# nrf7120E_enga_application register map
Vendor: Nordic Semiconductor; Series: nrf71; File version: 1
CPU: CM33 r0p4, little endian, MPU, FPU, 3 interrupt priority bits, 270 interrupts, 4 SAU regions
Registers are 32-bit, read-write, reset 0x0 unless marked. A register's access mark holds for its fields unless they carry their own. Offsets are from the block's base; [hi:lo] are bit positions; lines under a group give offsets from that group; {n}, {i} and the like mark numbered series; 'fields as' and 'values as' point back to an identical list.

## GLOBAL_MSPI00_NS — Multi serial peripheral interface 0
Base 0x4005B000
Same registers: GLOBAL_MSPI01_NS 0x4005C000, GLOBAL_MSPI00_S 0x5005B000, GLOBAL_MSPI01_S 0x5005C000
0x00 TASKS_START wo — Start operation.
  [0] TASKS_START
    1=Trigger task
0x04 TASKS_RESET wo — Reset the MSPI
  [0] TASKS_RESET
    1=Trigger task
0x08 TASKS_ACQUIRESEMAPHORE wo — Request the semaphore This task is exclusive to the 'peripheral' configuration
  [0] TASKS_ACQUIRESEMAPHORE
    1=Trigger task
0x0C TASKS_RELEASESEMAPHORE wo — Release the semaphore This task is exclusive to the 'peripheral' configuration
  [0] TASKS_RELEASESEMAPHORE
    1=Trigger task
0x100 EVENTS_CORE — Interrupt from the MSPI core
  [0] EVENTS_CORE
    0=NotGenerated (Event not generated); 1=Generated (Event generated)
0x104 EVENTS_DMA group — Peripheral events.
  0x00 EVENTS_DONE group — Peripheral events.
    0x00 LIST — Descriptor list is complete.
      [0] LIST
        values as EVENTS_CORE.EVENTS_CORE
    0x04 LISTPART — Descriptor list is partially complete. Threshold in CONFIG.LISTPARTTHRESH register has been passed.
      [0] LISTPART
        values as EVENTS_CORE.EVENTS_CORE
    0x08 SELECTJOB — Selected job is completed. Selection is done via CONFIG.SELECTJOBENABLE.
      [0] SELECTJOB
        values as EVENTS_CORE.EVENTS_CORE
    0x0C DATA — A job has been completed, i.e. the job's data has been completely transferred either to AXI or DMA bus, depending on direction.
      [0] DATA
        values as EVENTS_CORE.EVENTS_CORE
    0x10 JOB — A job has been fetched from the joblist.
      [0] JOB
        values as EVENTS_CORE.EVENTS_CORE
  0x14 ERROR — AXI bus error received.
    [0] ERROR
      values as EVENTS_CORE.EVENTS_CORE
  0x18 PAUSED — DMA paused with task TASKS_PAUSE.
    [0] PAUSED
      values as EVENTS_CORE.EVENTS_CORE
  0x1C RESET — DMA reset with task TASKS_RESET.
    [0] RESET
      values as EVENTS_CORE.EVENTS_CORE
  0x20 DONE — DMA transfer done
    [0] DONE
      values as EVENTS_CORE.EVENTS_CORE
  0x24 TXUNEXPECTEDIDLE — The MSPI core has gone into idle state at an unexpected time, this can happen if the TX buffer underflows, this event is followed by either DONE or ABORTED event.
    [0] TXUNEXPECTEDIDLE
      values as EVENTS_CORE.EVENTS_CORE
  0x28 INTERNALBUSERROR — An error occurred during the transfer of data internally in the MSPI, followed by either DONE or ABORTED event.
    [0] INTERNALBUSERROR
      values as EVENTS_CORE.EVENTS_CORE
  0x2C ABORTED — The MSPI DMA has aborted due to an error given in a separate event, and has attempted to complete any ongoing transactions, and stopped. The MSPI DMA is ready for a new transaction.
    [0] ABORTED
      values as EVENTS_CORE.EVENTS_CORE
0x134 EVENTS_IDLE — This event signifies that the MSPI core is no longer busy
  [0] EVENTS_IDLE
    values as EVENTS_CORE.EVENTS_CORE
0x138 EVENTS_OVERFLOW — The MSPI peripheral has received the specified number of bytes. Any data received after this event will be discarded if a new RX buffer has not been configured. This event is exclusive to the 'peripheral' configuration
  [0] EVENTS_OVERFLOW
    values as EVENTS_CORE.EVENTS_CORE
0x140 EVENTS_ACQUIRED — The semaphore has been acquired by the CPU This event is exclusive to the 'peripheral' configuration
  [0] EVENTS_ACQUIRED
    values as EVENTS_CORE.EVENTS_CORE
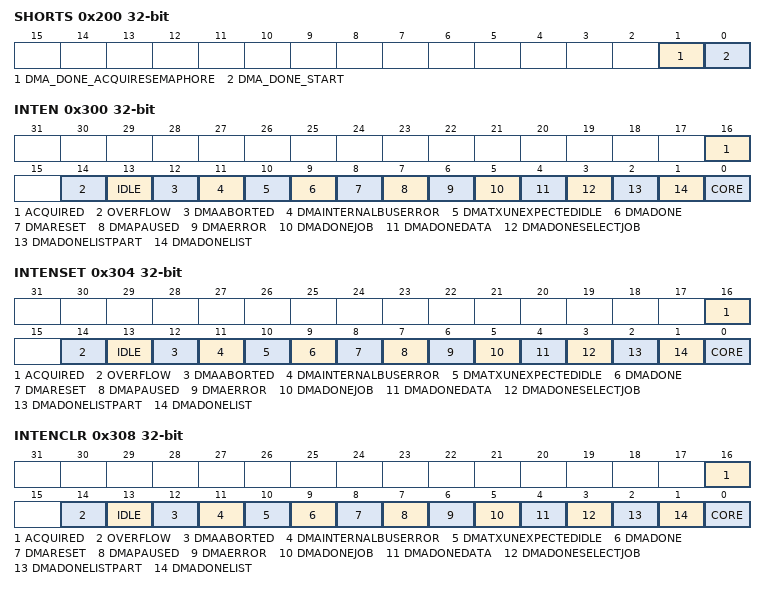
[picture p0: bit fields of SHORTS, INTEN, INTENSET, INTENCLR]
0x200 SHORTS — Shortcuts between local events and tasks
  [1] DMA_DONE_ACQUIRESEMAPHORE — Shortcut between event DMA.DONE and task ACQUIRESEMAPHORE
    0=Disabled (Disable shortcut); 1=Enabled (Enable shortcut)
  [0] DMA_DONE_START — Shortcut between event DMA.DONE and task START
    0=Disabled (Disable shortcut); 1=Enabled (Enable shortcut)
0x300 INTEN — Enable or disable interrupt
  [all] fields
    0=Disabled; 1=Enabled
  [16] ACQUIRED — Enable or disable interrupt for event ACQUIRED
  [14] OVERFLOW — Enable or disable interrupt for event OVERFLOW
  [13] IDLE — Enable or disable interrupt for event IDLE
  [12] DMAABORTED — Enable or disable interrupt for event DMAABORTED
  [11] DMAINTERNALBUSERROR — Enable or disable interrupt for event DMAINTERNALBUSERROR
  [10] DMATXUNEXPECTEDIDLE — Enable or disable interrupt for event DMATXUNEXPECTEDIDLE
  [9] DMADONE — Enable or disable interrupt for event DMADONE
  [8] DMARESET — Enable or disable interrupt for event DMARESET
  [7] DMAPAUSED — Enable or disable interrupt for event DMAPAUSED
  [6] DMAERROR — Enable or disable interrupt for event DMAERROR
  [5] DMADONEJOB — Enable or disable interrupt for event DMADONEJOB
  [4] DMADONEDATA — Enable or disable interrupt for event DMADONEDATA
  [3] DMADONESELECTJOB — Enable or disable interrupt for event DMADONESELECTJOB
  [2] DMADONELISTPART — Enable or disable interrupt for event DMADONELISTPART
  [1] DMADONELIST — Enable or disable interrupt for event DMADONELIST
  [0] CORE — Enable or disable interrupt for event CORE
0x304 INTENSET — Enable interrupt
  [all] fields
    on read: 0=Disabled (Read: Disabled); 1=Enabled (Read: Enabled) | on write: 1=Set (Enable)
  [16] ACQUIRED write-1-sets — Write '1' to enable interrupt for event ACQUIRED
  [14] OVERFLOW write-1-sets — Write '1' to enable interrupt for event OVERFLOW
  [13] IDLE write-1-sets — Write '1' to enable interrupt for event IDLE
  [12] DMAABORTED write-1-sets — Write '1' to enable interrupt for event DMAABORTED
  [11] DMAINTERNALBUSERROR write-1-sets — Write '1' to enable interrupt for event DMAINTERNALBUSERROR
  [10] DMATXUNEXPECTEDIDLE write-1-sets — Write '1' to enable interrupt for event DMATXUNEXPECTEDIDLE
  [9] DMADONE write-1-sets — Write '1' to enable interrupt for event DMADONE
  [8] DMARESET write-1-sets — Write '1' to enable interrupt for event DMARESET
  [7] DMAPAUSED write-1-sets — Write '1' to enable interrupt for event DMAPAUSED
  [6] DMAERROR write-1-sets — Write '1' to enable interrupt for event DMAERROR
  [5] DMADONEJOB write-1-sets — Write '1' to enable interrupt for event DMADONEJOB
  [4] DMADONEDATA write-1-sets — Write '1' to enable interrupt for event DMADONEDATA
  [3] DMADONESELECTJOB write-1-sets — Write '1' to enable interrupt for event DMADONESELECTJOB
  [2] DMADONELISTPART write-1-sets — Write '1' to enable interrupt for event DMADONELISTPART
  [1] DMADONELIST write-1-sets — Write '1' to enable interrupt for event DMADONELIST
  [0] CORE write-1-sets — Write '1' to enable interrupt for event CORE
0x308 INTENCLR — Disable interrupt
  [all] fields
    on read: 0=Disabled (Read: Disabled); 1=Enabled (Read: Enabled) | on write: 1=Clear (Disable)
  [16] ACQUIRED write-1-clears — Write '1' to disable interrupt for event ACQUIRED
  [14] OVERFLOW write-1-clears — Write '1' to disable interrupt for event OVERFLOW
  [13] IDLE write-1-clears — Write '1' to disable interrupt for event IDLE
  [12] DMAABORTED write-1-clears — Write '1' to disable interrupt for event DMAABORTED
  [11] DMAINTERNALBUSERROR write-1-clears — Write '1' to disable interrupt for event DMAINTERNALBUSERROR
  [10] DMATXUNEXPECTEDIDLE write-1-clears — Write '1' to disable interrupt for event DMATXUNEXPECTEDIDLE
  [9] DMADONE write-1-clears — Write '1' to disable interrupt for event DMADONE
  [8] DMARESET write-1-clears — Write '1' to disable interrupt for event DMARESET
  [7] DMAPAUSED write-1-clears — Write '1' to disable interrupt for event DMAPAUSED
  [6] DMAERROR write-1-clears — Write '1' to disable interrupt for event DMAERROR
  [5] DMADONEJOB write-1-clears — Write '1' to disable interrupt for event DMADONEJOB
  [4] DMADONEDATA write-1-clears — Write '1' to disable interrupt for event DMADONEDATA
  [3] DMADONESELECTJOB write-1-clears — Write '1' to disable interrupt for event DMADONESELECTJOB
  [2] DMADONELISTPART write-1-clears — Write '1' to disable interrupt for event DMADONELISTPART
  [1] DMADONELIST write-1-clears — Write '1' to disable interrupt for event DMADONELIST
  [0] CORE write-1-clears — Write '1' to disable interrupt for event CORE
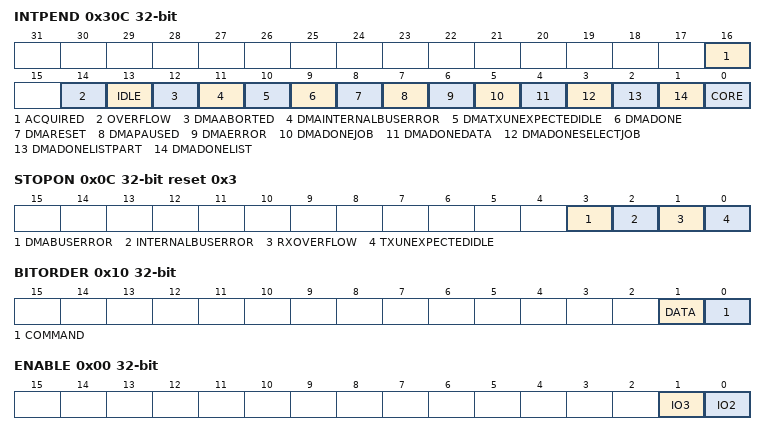
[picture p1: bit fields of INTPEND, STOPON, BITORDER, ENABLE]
0x30C INTPEND ro — Pending interrupts
  [all] fields
    on read: 0=NotPending (Read: Not pending); 1=Pending (Read: Pending)
  [16] ACQUIRED — Read pending status of interrupt for event ACQUIRED
  [14] OVERFLOW — Read pending status of interrupt for event OVERFLOW
  [13] IDLE — Read pending status of interrupt for event IDLE
  [12] DMAABORTED — Read pending status of interrupt for event DMAABORTED
  [11] DMAINTERNALBUSERROR — Read pending status of interrupt for event DMAINTERNALBUSERROR
  [10] DMATXUNEXPECTEDIDLE — Read pending status of interrupt for event DMATXUNEXPECTEDIDLE
  [9] DMADONE — Read pending status of interrupt for event DMADONE
  [8] DMARESET — Read pending status of interrupt for event DMARESET
  [7] DMAPAUSED — Read pending status of interrupt for event DMAPAUSED
  [6] DMAERROR — Read pending status of interrupt for event DMAERROR
  [5] DMADONEJOB — Read pending status of interrupt for event DMADONEJOB
  [4] DMADONEDATA — Read pending status of interrupt for event DMADONEDATA
  [3] DMADONESELECTJOB — Read pending status of interrupt for event DMADONESELECTJOB
  [2] DMADONELISTPART — Read pending status of interrupt for event DMADONELISTPART
  [1] DMADONELIST — Read pending status of interrupt for event DMADONELIST
  [0] CORE — Read pending status of interrupt for event CORE
0x400 ENABLE — Enables the MSPI
  [0] ENABLE — Enable the MSPI
0x404 CONFIG group — Unspecified
  0x00 TXBURSTLENGTH reset 0x8 — Transmit burst length
    [4:0] AMOUNT — Number of buffer lines
  0x04 RXBURSTLENGTH reset 0x8 — Receive burst length
    [4:0] AMOUNT — Number of buffer lines
  0x08 RXTRANSFERLENGTH reset 0x10 — Receive transfer full length
    [17:0] AMOUNT — Number of buffer lines
  0x0C STOPON reset 0x3 — Stop the DMA if the CORE goes into any of the enabled states.
    [3] DMABUSERROR — Terminate the transaction if a DMA.ERROR event is detected.
      0=Disabled; 1=Enabled
    [2] INTERNALBUSERROR — Terminate the transaction if a INTERNALBUSERROR event is detected.
      0=Disabled; 1=Enabled
    [1] RXOVERFLOW — This condition occurrs if the DMA attempts to write to the RX buffer in the CORE, but the buffer is full. When this bit is enabled the DMA will stop when the CORE buffer experiences a rx buffer overflow
      0=Disabled (Stop on rx overflow disabled.); 1=Enabled (Stop on rx overflow enabled.)
    [0] TXUNEXPECTEDIDLE — The CORE will go into idle if the CORE buffer is emptied, if the DMA still has data to transfer the CORE is not expected to go into idle state. This constitutes a buffer underflow. The CORE migth also go into idle if an error occurs.
      0=Disabled (Stop on tx unexpected idle disabled.); 1=Enabled (Stop on tx unexpected idle enabled.)
0x418 FORMAT group — Unspecified
  0x00 DFS — Data frame size
    [5:0] DFS
  0x04 BPP — Bits per pixel
    [5:0] BPP
      0=Reordering of pixels disabled; 4=4 Bits per pixel; 8=8 Bits per pixel; 16=16 Bits per pixel
  0x08 PIXELS — Number of pixels following the command
    [17:0] PIXELS — Number of pixels
  0x0C CILEN — Command/Instruction length
    [1:0] CILEN — Number of words
  0x10 BITORDER — This register selects if the data collected from system memory is transmitted MSB first or LSB first.
    [1] DATA — Selects the bit order of data
      0=MSB (Transmit MSB first); 1=LSB (Transmit LSB first)
    [0] COMMAND — Selects the bit order of command and address
      0=MSB (Transmit MSB first); 1=LSB (Transmit LSB first)
0x42C CUSTCMD group — Unspecified
  0x00 ENABLE — Custom command enable
    [1] IO3 — Enable custom command mode for IO3
      0=Disabled (Unspecified); 1=Enabled (Unspecified)
    [0] IO2 — Enable custom command mode for IO2
      0=Disabled (Unspecified); 1=Enabled (Unspecified)
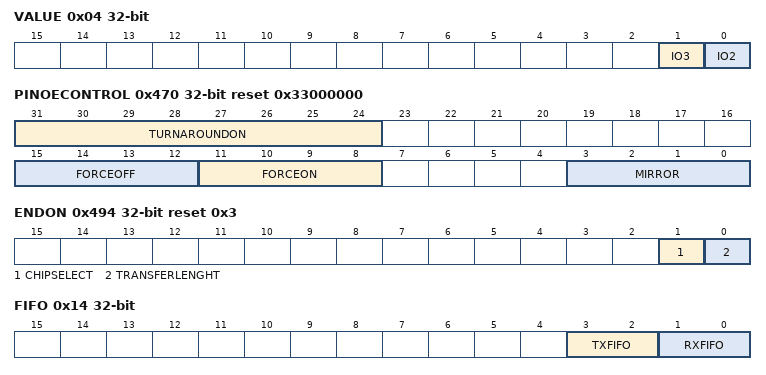
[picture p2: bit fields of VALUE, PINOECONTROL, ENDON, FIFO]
  0x04 VALUE — Custom command value
    [1] IO3 — Value to override IO3 to in custom command mode
    [0] IO2 — Value to override IO2 to in custom command mode
0x470 PINOECONTROL reset 0x33000000 — Override and control the output enable signal to the GPIO pads
  [31:24] TURNAROUNDON — Time needed for pin output driver to turn on (in core clock cycles)
    0=Disabled (Unspecified)
  [15:12] FORCEOFF — Force pin direction to be input
    1=EnableIO0 (Forcing off enabled output for IO0); 2=EnableIO1 (Forcing off enabled output for IO1); 4=EnableIO2 (Forcing off enabled output for IO2); 8=EnableIO3 (Forcing off enabled output for IO3); 15=EnableAll (Forcing off enabled output for all data lines); 0=Disabled (Forcing off Output Enable is disabled)
  [11:8] FORCEON — Force pin direction to be output
    1=EnableIO0 (Forcing on enabled output for IO0); 2=EnableIO1 (Forcing on enabled output for IO1); 4=EnableIO2 (Forcing on enabled output for IO2); 8=EnableIO3 (Forcing on enabled output for IO3); 15=EnableAll (Forcing on enabled output for all data lines); 0=Disabled (Forcing on Output Enable is disabled)
  [3:0] MIRROR — Enable mirroring of output enable of pin 0 for corresponding bit
    1=EnableIO0 (Enable mirroring on output enable for IO0); 2=EnableIO1 (Enable mirroring on output enable for IO1); 4=EnableIO2 (Enable mirroring on output enable for IO2); 8=EnableIO3 (Enable mirroring on output enable for IO3); 15=EnableAll (Enable mirroring on output enable for all data lines); 0=Disabled (Enabling mirroring on Output Enable is disabled)
0x490 TMOD — Transfer Mode of the MSPI when used as peripheral This register is exclusive to the 'peripheral' configuration
  [1:0] TMOD
    1=TXONLY (Transmit only mode; Or Write in enhanced SPI operating mode); 2=RXONLY (Receive only mode; Or Read in enhanced SPI operating mode)
0x494 ENDON reset 0x3 — End the DMA if the MSPI meets any of the defined states This task is exclusive to the 'peripheral' configuration
  [1] CHIPSELECT — End the DMA transaction when chip select goes inactive
  [0] TRANSFERLENGHT ro — End the DMA transaction when the transferlength has been met
0x4B0 RXD group — Unspecified
  0x00 AMOUNT ro — DMA data amount
    [23:0] AMOUNT
0x4D0 TXD group — Unspecified
  0x00 AMOUNT ro — DMA data amount
    [23:0] AMOUNT
0x500 DMA group — Unspecified
  0x00 STATUS group — EasyVDMA status registers.
    0x00 BYTECOUNT ro — Number of bytes sent or received during processing of current descriptor list
    0x04 ATTRIBUTE ro — Latest job attribute being processed.
      [5:0] ATTRIBUTE
    0x08 ADDRESS ro — Latest address being accessed.
    0x0C JOBCOUNT ro — Number of completed jobs in current descriptor list.
    0x10 BUSERROR ro — AXI bus error status.
      [2:0] BUSERROR — AXI bus error type
        0=NoError (There are no errors.); 1=ReadError (Error related to memory when reading joblist, or error related to memory/register when reading data.); 2=ReadDecodeError (Error related to the joblist address when reading joblist, or error related to address when reading memory/register.); 3=WriteError (Error related to memory/register when writing data.); 4=WriteDecodeError (Error related to the memory/register address when writing data.)
    0x14 FIFO ro — Data fifo status.
      [3:2] TXFIFO — Peripheral-to-Memory direction data fifo status
        0=Empty (Fifo is empty.); 1=NotEmpty (Fifo contains data.); 2=Full (Fifo is full.)
      [1:0] RXFIFO — Memory-to-Peripheral direction data fifo status
        values as TXFIFO
    0x18 ACTIVE ro — DMA activity state.
      [0] ACTIVE
        0=Idle (DMA is in idle state.); 1=Active (Data is being transferred.)
  0x100 CONFIG group — EasyVDMA configuration registers
    0x00 BUFFERFILL — Data to be used when data is sent with BufferFill attribute
      [7:0] BUFFERFILL
    0x04 LISTPTR — Start address of descriptor list
    0x08 LISTPARTTHRESH — Number of jobs to process before generating event EVENTS_DONE.LISTPART to signal that descriptor list is partially completed.
      [15:0] LISTPARTTHRESH — Threshold value.
0x900 CONTROLLERCORE group — Unspecified
  0x00 CORE group — Unspecified
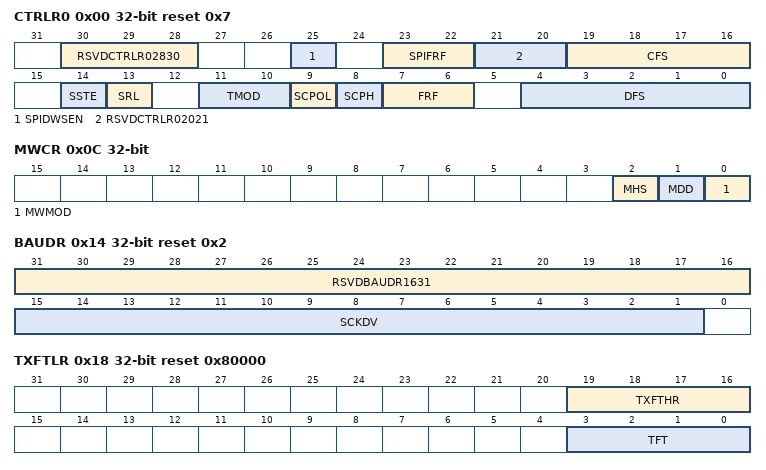
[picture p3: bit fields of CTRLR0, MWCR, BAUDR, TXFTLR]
    0x00 CTRLR0 reset 0x7 — Control Register 0
      [30:28] RSVDCTRLR02830 ro
      [25] SPIDWSEN — Enable Dynamic wait states in SPI mode of operation. This field is only applicable when CTRLR0.FRF is set to 0 (Motorola SPI Frame Format).
        0=DISABLE (Disable SPI Dynamic Wait State); 1=ENABLE (Enable SPI Dynamic Wait State)
      [23:22] SPIFRF — SPI Frame Format
        0=SPI_STANDARD (Standard SPI Format); 1=SPI_DUAL (Dual SPI Format); 2=SPI_QUAD (Quad SPI Format); 3=SPI_OCTAL (Octal SPI Format)
      [21:20] RSVDCTRLR02021 ro
      [19:16] CFS — Control Frame Size.
        {v}=SIZE_{v+1:02}_BIT ({v+1:02}-bit Control Word) (v=0..15)
      [14] SSTE — Target Select Toggle Enable.
        0=TOGGLE_DISABLE (ss_*_n will stay low and sclk will run continuously for the duration of the transfer); 1=TOGGLE_EN (ss_*_n line will toggle between consecutive data frames, with the serial clock (sclk) being held to its default value while ss_*_n is high)
      [13] SRL — Shift Register Loop.
        0=NORMAL_MODE (Normal mode operation); 1=TESTING_MODE (Test Mode Operation)
      [11:10] TMOD — Transfer Mode.
        0=TX_AND_RX (Transmit & Receive; Not Applicable in enhanced SPI operating mode or when SSIC_HAS_TX_RX_EN is set to 0); 1=TX_ONLY (Transmit only mode; Or Write in enhanced SPI operating mode); 2=RX_ONLY (Receive only mode; Or Read in enhanced SPI operating mode); 3=EEPROM_READ (EEPROM Read mode; Not Applicable in enhanced SPI operating mode)
      [9] SCPOL — Serial Clock Polarity.
        0=INACTIVE_LOW (Inactive state of serial clock is low); 1=INACTIVE_HIGH (Inactive state of serial clock is high)
      [8] SCPH — Serial Clock Phase.
        0=MIDDLE_BIT (Serial clock toggles in middle of first bit); 1=START_BIT (Serial clock toggles at start of first bit)
      [7:6] FRF — Frame Format.
        0=SPI (Motorola SPI Frame Format); 1=SSP (Texas Instruments SSP Frame Format); 2=MICROWIRE (National Semiconductors Microwire Frame Format)
      [4:0] DFS — Data Frame Size.
        {v}=DFS_{v+1:02}_BIT ({v+1:02}-bit serial data transfer) (v=3..31)
    0x04 CTRLR1 — Control Register 1
      [15:0] NDF — Number of Data Frames.
    0x08 SSIENR — SSI Enable Register
      [0] SSICEN — SSI Enable.
        0=DISABLE (Disables MSPI CORE); 1=ENABLED (Enables MSPI CORE)
    0x0C MWCR — Microwire Control Register
      [2] MHS — Microwire Handshaking.
        0=DISABLE (handshaking interface is disabled); 1=ENABLED (handshaking interface is enabled)
      [1] MDD — Microwire Control.
        0=RECEIVE (SSI receives data); 1=TRANSMIT (SSI transmits data)
      [0] MWMOD — Microwire Transfer Mode.
        0=NON_SEQUENTIAL (Non-Sequential Transfer); 1=SEQUENTIAL (Sequential Transfer)
    0x10 SER — Target Enable Register
      [3:0] SER — Chip Select Enable Flag.
    0x14 BAUDR reset 0x2 — Baud Rate Select
      [31:16] RSVDBAUDR1631 ro
      [15:1] SCKDV — SSI Clock Divider.
    0x18 TXFTLR reset 0x80000 — Transmit FIFO Threshold Level
      [19:16] TXFTHR — Transfer start FIFO level.
      [3:0] TFT — Transmit FIFO Threshold.
    0x1C RXFTLR — Receive FIFO Threshold Level
      [3:0] RFT — Receive FIFO Threshold.
    0x20 TXFLR — Transmit FIFO Level Register
      [4:0] TXTFL ro — Transmit FIFO Level.
    0x24 RXFLR — Receive FIFO Level Register
      [4:0] RXTFL ro — Receive FIFO Level.
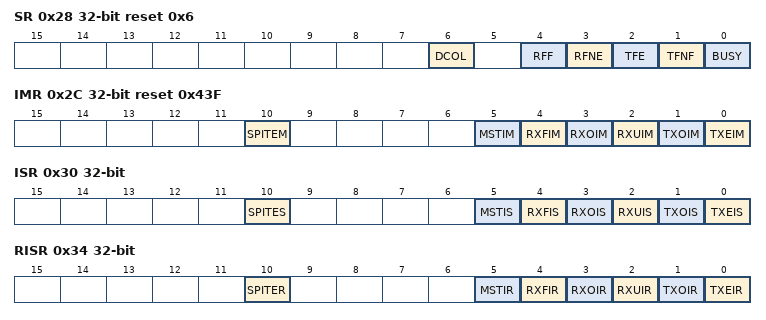
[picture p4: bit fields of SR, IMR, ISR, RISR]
    0x28 SR reset 0x6 — Status Register
      [6] DCOL ro — Data Collision Error.
        0=NO_ERROR_CONDITION; 1=TX_COLLISION_ERROR (Transmit Data Collision Error)
      [4] RFF ro — Receive FIFO Full.
        0=NOT_FULL (Receive FIFO is not full); 1=FULL (Receive FIFO is full)
      [3] RFNE ro — Receive FIFO Not Empty.
        0=EMPTY (Receive FIFO is empty); 1=NOT_EMPTY (Receive FIFO is not empty)
      [2] TFE ro — Transmit FIFO Empty.
        0=NOT_EMPTY (Transmit FIFO is not empty); 1=EMPTY (Transmit FIFO is empty)
      [1] TFNF ro — Transmit FIFO Not Full.
        0=FULL (Tx FIFO is full); 1=NOT_FULL (Tx FIFO is not Full)
      [0] BUSY ro — SSI Busy Flag.
        0=INACTIVE (MSPI CORE is idle or disabled); 1=ACTIVE (MSPI CORE is actively transferring data)
    0x2C IMR reset 0x43F — Interrupt Mask Register
      [10] SPITEM — SPI Transmit Error Interrupt Mask
        0=MASKED (ssi_spite_intr interrupt is masked); 1=UNMASKED (ssi_spite_intr interrupt is not masked)
      [5] MSTIM — Multi-Controller Contention Interrupt Mask. This bit field is not present if the MSPI CORE is configured as a serial-target device.
        0=MASKED (ssi_mst_intr interrupt is masked); 1=UNMASKED (ssi_mst_intr interrupt is not masked)
      [4] RXFIM — Receive FIFO Full Interrupt Mask
        0=MASKED (ssi_rxf_intr interrupt is masked); 1=UNMASKED (ssi_rxf_intr interrupt is not masked)
      [3] RXOIM — Receive FIFO Overflow Interrupt Mask
        0=MASKED (ssi_rxo_intr interrupt is masked); 1=UNMASKED (ssi_rxo_intr interrupt is not masked)
      [2] RXUIM — Receive FIFO Underflow Interrupt Mask
        0=MASKED (ssi_rxu_intr interrupt is masked); 1=UNMASKED (ssi_rxu_intr interrupt is not masked)
      [1] TXOIM — Transmit FIFO Overflow Interrupt Mask
        0=MASKED (ssi_txo_intr interrupt is masked); 1=UNMASKED (ssi_txo_intr interrupt is not masked)
      [0] TXEIM — Transmit FIFO Empty Interrupt Mask
        0=MASKED (ssi_txe_intr interrupt is masked); 1=UNMASKED (ssi_txe_intr interrupt is not masked)
    0x30 ISR — Interrupt Status Register
      [10] SPITES ro — SPI Transmit Error Interrupt
        0=INACTIVE (ssi_spite_intr interrupt is not active after masking); 1=ACTIVE (ssi_spite_intr interrupt is active after masking)
      [5] MSTIS ro — Multi-Controller Contention Interrupt Status. This bit field is not present
        0=INACTIVE (ssi_mst_intr interrupt is not active after masking); 1=ACTIVE (ssi_mst_intr interrupt is active after masking)
      [4] RXFIS ro — Receive FIFO Full Interrupt Status
        0=INACTIVE (ssi_rxf_intr interrupt is not active after masking); 1=ACTIVE (ssi_rxf_intr interrupt is active after masking)
      [3] RXOIS ro — Receive FIFO Overflow Interrupt Status
        0=INACTIVE (ssi_rxo_intr interrupt is not active after masking); 1=ACTIVE (ssi_rxo_intr interrupt is active after masking)
      [2] RXUIS ro — Receive FIFO Underflow Interrupt Status
        0=INACTIVE (ssi_rxu_intr interrupt is not active after masking); 1=ACTIVE (ssi_rxu_intr interrupt is active after masking)
      [1] TXOIS ro — Transmit FIFO Overflow Interrupt Status
        0=INACTIVE (ssi_txo_intr interrupt is not active after masking); 1=ACTIVE (ssi_txo_intr interrupt is active after masking)
      [0] TXEIS ro — Transmit FIFO Empty Interrupt Status
        0=INACTIVE (ssi_txe_intr interrupt is not active after masking); 1=ACTIVE (ssi_txe_intr interrupt is active after masking)
    0x34 RISR — Raw Interrupt Status Register
      [10] SPITER ro — SPI Transmit Error Interrupt status.
        0=INACTIVE (ssi_spite_intr interrupt is not active prior to masking); 1=ACTIVE (ssi_spite_intr interrupt is active prior to masking)
      [5] MSTIR ro — Multi-Controller Contention Raw Interrupt Status. This bit field is not present if the MSPI CORE is configured as a serial-target device.
        0=INACTIVE (ssi_mst_intr interrupt is not active prior masking); 1=ACTIVE (ssi_mst_intr interrupt is active prior to masking)
      [4] RXFIR ro — Receive FIFO Full Raw Interrupt Status
        0=INACTIVE (ssi_rxf_intr interrupt is not active prior masking); 1=ACTIVE (ssi_rxf_intr interrupt is active prior to masking)
      [3] RXOIR ro — Receive FIFO Overflow Raw Interrupt Status
        0=INACTIVE (ssi_rxo_intr interrupt is not active prior masking); 1=ACTIVE (ssi_rxo_intr interrupt is active prior to masking)
      [2] RXUIR ro — Receive FIFO Underflow Raw Interrupt Status
        0=INACTIVE (ssi_rxu_intr interrupt is not active prior masking); 1=ACTIVE (ssi_rxu_intr interrupt is active prior to masking)
      [1] TXOIR ro — Transmit FIFO Overflow Raw Interrupt Status
        0=INACTIVE (ssi_txo_intr interrupt is not active prior masking); 1=ACTIVE (ssi_txo_intr interrupt is active prior to masking)
      [0] TXEIR ro — Transmit FIFO Empty Raw Interrupt Status
        0=INACTIVE (ssi_txe_intr interrupt is not active prior masking); 1=ACTIVE (ssi_txe_intr interrupt is active prior to masking)
    0x38 TXEICR — Transmit FIFO Error Interrupt Clear Register Register
      [0] TXEICR ro — Clear Transmit FIFO Overflow/Underflow Interrupt.
    0x3C RXOICR — Receive FIFO Overflow Interrupt Clear Register
      [0] RXOICR ro — Clear Receive FIFO Overflow Interrupt.
    0x40 RXUICR — Receive FIFO Underflow Interrupt Clear Register
      [0] RXUICR ro — Clear Receive FIFO Underflow Interrupt.
    0x44 MSTICR — Multi-Controller Interrupt Clear Register
      [0] MSTICR ro — Clear Multi-Controller Contention Interrupt.
    0x48 ICR — Interrupt Clear Register
      [0] ICR ro — Clear Interrupts.
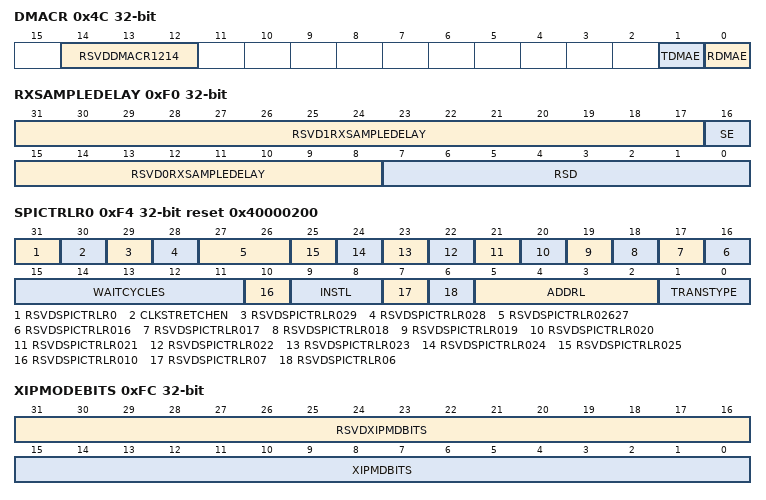
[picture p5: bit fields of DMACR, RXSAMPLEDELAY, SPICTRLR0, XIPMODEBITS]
    0x4C DMACR — DMA Control Register
      [14:12] RSVDDMACR1214 ro
      [1] TDMAE — Transmit DMA Enable. This bit enables/disables the transmit FIFO DMA channel.
        0=DISABLE (Transmit DMA disabled); 1=ENABLED (Transmit DMA enabled)
      [0] RDMAE — Receive DMA Enable. This bit enables/disables the receive FIFO DMA channel.
        0=DISABLE (Receive DMA disabled); 1=ENABLED (Receive DMA enabled)
    0x50 DMATDLR — DMA Transmit Data Level
      [3:0] DMATDL — Transmit Data Level. This bit field controls the level at which a DMA request is made by the transmit logic. It is equal to the watermark level; that is, the dma_tx_req signal is generated when the number of valid data entries in the transmit FIFO is equal to or below this field value, and TDMAE = 1.
    0x54 DMARDLR — DMA Receive Data Level
      [3:0] DMARDL — Receive Data Level. This bit field controls the level at which a DMA request is made by the receive logic. The watermark level = DMARDL+1; that is, dma_rx_req is generated when the number of valid data entries in the receive FIFO is equal to or above this field value + 1, and RDMAE=1.
    0x58 IDR reset 0x51535049 — Identification Register
      [31:0] IDCODE ro — Identification code. The register contains the identification code of the peripheral, which is written into the register at configuration time using CoreConsultant.
    0x5C SSICVERSIONID reset 0x3230312A — MSPI CORE component version
      [31:0] SSICCOMPVERSION ro — Contains the hex representation of the Synopsys component version. Consists of ASCII value for each number in the version, followed by *. For example 31_30_33_2A represents the version 1.03*.
    {0x60+4k} DR[{k}] (k=0..35) — Description collection: MSPI CORE Data Register 0
      [31:0] DR — Data Register. When writing to this register, you must right-justify the data. Read data are automatically right-justified.
    0xF0 RXSAMPLEDELAY
      [31:17] RSVD1RXSAMPLEDELAY ro
      [16] SE — Receive Data (rxd) Sampling Edge. This register is used to decide the sampling edge for RXD signal with ssi_clk. Then this bit is set to 1 then negative edge of ssi_clk will be used to sample the incoming data, otherwise positive edge will be used for sampling.
      [15:8] RSVD0RXSAMPLEDELAY ro
      [7:0] RSD — Receive Data (rxd) Sample Delay. This register is used to delay the sample of the rxd input port. Each value
    0xF4 SPICTRLR0 reset 0x40000200 — SPI_CTRLR0 - SPI Control Register
      [31] RSVDSPICTRLR0 ro
      [30] CLKSTRETCHEN — Enables clock stretching capability in SPI transfers.
      [29] RSVDSPICTRLR029 ro
      [28] RSVDSPICTRLR028 ro
      [27:26] RSVDSPICTRLR02627 ro
      [n] RSVDSPICTRLR{n:03} ro (n=16..25)
      [15:11] WAITCYCLES — Wait cycles in SPI mode between control frames transmit and data transmit/reception. Specified as number of SPI clock cycles.
      [10] RSVDSPICTRLR010 ro
      [9:8] INSTL — Enhanced SPI mode instruction length in bits.
        0=INST_L0 (No Instruction); 1=INST_L4 (4 bit Instruction length); 2=INST_L8 (8 bit Instruction length); 3=INST_L16 (16 bit Instruction length)
      [7] RSVDSPICTRLR07 ro
      [6] RSVDSPICTRLR06 ro
      [5:2] ADDRL — This bit defines Length of Address to be transmitted. Only after this much bits are programmed in to the FIFO the transfer can begin.
        0=ADDR_L0 (No Address); 1=ADDR_L4 (4 bit Address length); 2=ADDR_L8 (8 bit Address length); 3=ADDR_L12 (12 bit Address length); 4=ADDR_L16 (16 bit Address length); 5=ADDR_L20 (20 bit Address length); 6=ADDR_L24 (24 bit Address length); 7=ADDR_L28 (28 bit Address length); 8=ADDR_L32 (32 bit Address length); 9=ADDR_L36 (36 bit Address length); 10=ADDR_L40 (40 bit Address length); 11=ADDR_L44 (44 bit Address length); 12=ADDR_L48 (48 bit Address length); 13=ADDR_L52 (52 bit Address length); 14=ADDR_L56 (56 bit Address length); 15=ADDR_L60 (60 bit Address length)
      [1:0] TRANSTYPE — Address and instruction transfer format.
        0=TT0 (Instruction and Address will be sent in Standard SPI Mode.); 1=TT1 (Instruction will be sent in Standard SPI Mode and Address will be sent in the mode specified by CTRLR0.SPI_FRF.); 2=TT2 (Both Instruction and Address will be sent in the mode specified by SPI_FRF.); 3=TT3 (Dual Octal mode, the address and instruction are transferred in octal mode and data is transferred on 16 data lines.)
    0x118 SPICTRLR1 — SPI Control 1 register
      [31:20] RSVDSPICTRLR12031 ro
      [19:16] CSMINHIGH — Chip-Select Minimum HIGH period.
      [15:9] RSVDSPICTRLR1 ro
      [8:5] MAXWS — Maximum wait cycles allowed per transaction.
      [4:3] RSVDSPICTRLR134 ro
      [2:0] DYNWS — SPI Dynamic Wait states field.
    0x11C SPITECR — SPI Transmit Error Interrupt Clear Register
      [0] SPITECR ro — Clear SPI Transmit Error interrupt.
0x900 PERIPHERALCORE group (alternate view of CONTROLLERCORE) — Unspecified
  0x00 CORE group — Unspecified
    0x00 CTRLR0 reset 0x80000007 — Control Register 0
      [31] SSIISMST — This field selects if MSPI CORE is working in Controller or Target mode
        0=TARGET (MSPI CORE is Target); 1=CONTROLLER (MSPI CORE is Controller)
      [30:28] RSVDCTRLR02830 ro
      [25] SPIDWSEN — Enable Dynamic wait states in SPI mode of operation. This field is only applicable when CTRLR0.FRF is set to 0 (Motorola SPI Frame Format).
        values as CONTROLLERCORE.CORE.CTRLR0.SPIDWSEN
      [23:22] SPIFRF — SPI Frame Format
        values as CONTROLLERCORE.CORE.CTRLR0.SPIFRF
      [21:20] RSVDCTRLR02021 ro
      [19:16] CFS — Control Frame Size.
        {v}=SIZE_{v+1:02}_BIT ({v+1:02}-bit Control Word) (v=0..15)
      [14] SSTE — Target Select Toggle Enable.
        values as CONTROLLERCORE.CORE.CTRLR0.SSTE
      [13] SRL — Shift Register Loop.
        values as CONTROLLERCORE.CORE.CTRLR0.SRL
      [12] SLVOE — Target Output Enable.
        0=ENABLED (Target Output is enabled); 1=DISABLED (Target Output is disabled)
      [11:10] TMOD — Transfer Mode.
        values as CONTROLLERCORE.CORE.CTRLR0.TMOD
      [9] SCPOL — Serial Clock Polarity.
        values as CONTROLLERCORE.CORE.CTRLR0.SCPOL
      [8] SCPH — Serial Clock Phase.
        values as CONTROLLERCORE.CORE.CTRLR0.SCPH
      [7:6] FRF — Frame Format.
        values as CONTROLLERCORE.CORE.CTRLR0.FRF
      [4:0] DFS — Data Frame Size.
        values as CONTROLLERCORE.CORE.CTRLR0.DFS
    0x04 CTRLR1 — Control Register 1
      [15:0] NDF — Number of Data Frames.
    0x08 SSIENR — SSI Enable Register
      fields as CONTROLLERCORE.CORE.SSIENR
    0x0C MWCR — Microwire Control Register
      fields as CONTROLLERCORE.CORE.MWCR
    0x10 SER — Target Enable Register
      [3:0] SER — Chip Select Enable Flag.
    0x14 BAUDR reset 0x2 — Baud Rate Select
      [31:16] RSVDBAUDR1631 ro
      [15:1] SCKDV — SSI Clock Divider.
    0x18 TXFTLR reset 0x80000 — Transmit FIFO Threshold Level
      fields as CONTROLLERCORE.CORE.TXFTLR
    0x1C RXFTLR — Receive FIFO Threshold Level
      [3:0] RFT — Receive FIFO Threshold.
    0x20 TXFLR — Transmit FIFO Level Register
      [4:0] TXTFL ro — Transmit FIFO Level.
    0x24 RXFLR — Receive FIFO Level Register
      [4:0] RXTFL ro — Receive FIFO Level.
    0x28 SR reset 0x6 — Status Register
      [6] DCOL ro — Data Collision Error.
        values as CONTROLLERCORE.CORE.SR.DCOL
      [5] TXE ro — Transmission Error.
        0=NO_ERROR; 1=TX_ERROR (Transmission Error)
      [4] RFF ro — Receive FIFO Full.
        values as CONTROLLERCORE.CORE.SR.RFF
      [3] RFNE ro — Receive FIFO Not Empty.
        values as CONTROLLERCORE.CORE.SR.RFNE
      [2] TFE ro — Transmit FIFO Empty.
        values as CONTROLLERCORE.CORE.SR.TFE
      [1] TFNF ro — Transmit FIFO Not Full.
        0=FULL (Tx FIFO is full); 1=NOT_FULL (Tx FIFO is not Full)
      [0] BUSY ro — SSI Busy Flag.
        values as CONTROLLERCORE.CORE.SR.BUSY
    0x2C IMR reset 0x43F — Interrupt Mask Register
      fields as CONTROLLERCORE.CORE.IMR
    0x30 ISR — Interrupt Status Register
      fields as CONTROLLERCORE.CORE.ISR
    0x34 RISR — Raw Interrupt Status Register
      fields as CONTROLLERCORE.CORE.RISR
    0x38 TXEICR — Transmit FIFO Error Interrupt Clear Register Register
      [0] TXEICR ro — Clear Transmit FIFO Overflow/Underflow Interrupt.
    0x3C RXOICR — Receive FIFO Overflow Interrupt Clear Register
      [0] RXOICR ro — Clear Receive FIFO Overflow Interrupt.
    0x40 RXUICR — Receive FIFO Underflow Interrupt Clear Register
      [0] RXUICR ro — Clear Receive FIFO Underflow Interrupt.
    0x44 MSTICR — Multi-Controller Interrupt Clear Register
      [0] MSTICR ro — Clear Multi-Controller Contention Interrupt.
    0x48 ICR — Interrupt Clear Register
      [0] ICR ro — Clear Interrupts.
    0x4C DMACR — DMA Control Register
      fields as CONTROLLERCORE.CORE.DMACR
    0x50 DMATDLR — DMA Transmit Data Level
      fields as CONTROLLERCORE.CORE.DMATDLR
    0x54 DMARDLR — DMA Receive Data Level
      fields as CONTROLLERCORE.CORE.DMARDLR
    0x58 IDR reset 0x51535049 — Identification Register
      fields as CONTROLLERCORE.CORE.IDR
    0x5C SSICVERSIONID reset 0x3230312A — MSPI CORE component version
      fields as CONTROLLERCORE.CORE.SSICVERSIONID
    {0x60+4k} DR[{k}] (k=0..35) — Description collection: MSPI CORE Data Register 0
      fields as CONTROLLERCORE.CORE.DR[0]
    0xF0 RXSAMPLEDELAY
      fields as CONTROLLERCORE.CORE.RXSAMPLEDELAY
    0xF4 SPICTRLR0 reset 0x40000200 — SPI_CTRLR0 - SPI Control Register
      fields as CONTROLLERCORE.CORE.SPICTRLR0
    0x118 SPICTRLR1 — SPI Control 1 register
      fields as CONTROLLERCORE.CORE.SPICTRLR1
    0x11C SPITECR — SPI Transmit Error Interrupt Clear Register
      [0] SPITECR ro — Clear SPI Transmit Error interrupt.
0x900 XIPCORE group (alternate view of CONTROLLERCORE) — Unspecified
  0x00 CORE group — Unspecified
    0x00 CTRLR0 reset 0x7 — Control Register 0
      [30:28] RSVDCTRLR02830 ro
      [23:22] SPIFRF — SPI Frame Format
        values as CONTROLLERCORE.CORE.CTRLR0.SPIFRF
      [21:20] RSVDCTRLR02021 ro
      [19:16] CFS — Control Frame Size.
        {v}=SIZE_{v+1:02}_BIT ({v+1:02}-bit Control Word) (v=0..15)
      [14] SSTE — Target Select Toggle Enable.
        values as CONTROLLERCORE.CORE.CTRLR0.SSTE
      [13] SRL — Shift Register Loop.
        values as CONTROLLERCORE.CORE.CTRLR0.SRL
      [11:10] TMOD — Transfer Mode.
        values as CONTROLLERCORE.CORE.CTRLR0.TMOD
      [9] SCPOL — Serial Clock Polarity.
        values as CONTROLLERCORE.CORE.CTRLR0.SCPOL
      [8] SCPH — Serial Clock Phase.
        values as CONTROLLERCORE.CORE.CTRLR0.SCPH
      [7:6] FRF — Frame Format.
        values as CONTROLLERCORE.CORE.CTRLR0.FRF
      [4:0] DFS — Data Frame Size.
        values as CONTROLLERCORE.CORE.CTRLR0.DFS
    0x04 CTRLR1 — Control Register 1
      [15:0] NDF — Number of Data Frames.
    0x08 SSIENR — SSI Enable Register
      fields as CONTROLLERCORE.CORE.SSIENR
    0x0C MWCR — Microwire Control Register
      fields as CONTROLLERCORE.CORE.MWCR
    0x10 SER — Target Enable Register
      [3:0] SER — Chip Select Enable Flag.
    0x14 BAUDR reset 0x2 — Baud Rate Select
      [31:16] RSVDBAUDR1631 ro
      [15:1] SCKDV — SSI Clock Divider.
    0x18 TXFTLR reset 0x80000 — Transmit FIFO Threshold Level
      fields as CONTROLLERCORE.CORE.TXFTLR
    0x1C RXFTLR — Receive FIFO Threshold Level
      [3:0] RFT — Receive FIFO Threshold.
    0x20 TXFLR — Transmit FIFO Level Register
      [4:0] TXTFL ro — Transmit FIFO Level.
    0x24 RXFLR — Receive FIFO Level Register
      [4:0] RXTFL ro — Receive FIFO Level.
    0x28 SR reset 0x6 — Status Register
      fields as CONTROLLERCORE.CORE.SR
    0x2C IMR reset 0x7F — Interrupt Mask Register
      [6] XRXOIM — XIP Receive FIFO Overflow Interrupt Mask
        0=MASKED (ssi_xrxo_intr interrupt is masked); 1=UNMASKED (ssi_xrxo_intr interrupt is not masked)
      [5] MSTIM — Multi-Controller Contention Interrupt Mask. This bit field is not present if the MSPI CORE is configured as a serial-target device.
        values as CONTROLLERCORE.CORE.IMR.MSTIM
      [4] RXFIM — Receive FIFO Full Interrupt Mask
        values as CONTROLLERCORE.CORE.IMR.RXFIM
      [3] RXOIM — Receive FIFO Overflow Interrupt Mask
        values as CONTROLLERCORE.CORE.IMR.RXOIM
      [2] RXUIM — Receive FIFO Underflow Interrupt Mask
        values as CONTROLLERCORE.CORE.IMR.RXUIM
      [1] TXOIM — Transmit FIFO Overflow Interrupt Mask
        values as CONTROLLERCORE.CORE.IMR.TXOIM
      [0] TXEIM — Transmit FIFO Empty Interrupt Mask
        values as CONTROLLERCORE.CORE.IMR.TXEIM
    0x30 ISR — Interrupt Status Register
      [6] XRXOIS ro — XIP Receive FIFO Overflow Interrupt Status
        0=INACTIVE (ssi_xrxo_intr interrupt is not active after masking); 1=ACTIVE (ssi_xrxo_intr interrupt is active after masking)
      [5] MSTIS ro — Multi-Controller Contention Interrupt Status. This bit field is not present
        values as CONTROLLERCORE.CORE.ISR.MSTIS
      [4] RXFIS ro — Receive FIFO Full Interrupt Status
        values as CONTROLLERCORE.CORE.ISR.RXFIS
      [3] RXOIS ro — Receive FIFO Overflow Interrupt Status
        values as CONTROLLERCORE.CORE.ISR.RXOIS
      [2] RXUIS ro — Receive FIFO Underflow Interrupt Status
        values as CONTROLLERCORE.CORE.ISR.RXUIS
      [1] TXOIS ro — Transmit FIFO Overflow Interrupt Status
        values as CONTROLLERCORE.CORE.ISR.TXOIS
      [0] TXEIS ro — Transmit FIFO Empty Interrupt Status
        values as CONTROLLERCORE.CORE.ISR.TXEIS
    0x34 RISR — Raw Interrupt Status Register
      [6] XRXOIR ro — XIP Receive FIFO Overflow Raw Interrupt Status
        0=INACTIVE (ssi_xrxo_intr interrupt is not active prior masking); 1=ACTIVE (ssi_xrxo_intr interrupt is active prior to masking)
      [5] MSTIR ro — Multi-Controller Contention Raw Interrupt Status. This bit field is not present if the MSPI CORE is configured as a serial-target device.
        values as CONTROLLERCORE.CORE.RISR.MSTIR
      [4] RXFIR ro — Receive FIFO Full Raw Interrupt Status
        values as CONTROLLERCORE.CORE.RISR.RXFIR
      [3] RXOIR ro — Receive FIFO Overflow Raw Interrupt Status
        values as CONTROLLERCORE.CORE.RISR.RXOIR
      [2] RXUIR ro — Receive FIFO Underflow Raw Interrupt Status
        values as CONTROLLERCORE.CORE.RISR.RXUIR
      [1] TXOIR ro — Transmit FIFO Overflow Raw Interrupt Status
        values as CONTROLLERCORE.CORE.RISR.TXOIR
      [0] TXEIR ro — Transmit FIFO Empty Raw Interrupt Status
        values as CONTROLLERCORE.CORE.RISR.TXEIR
    0x38 TXEICR — Transmit FIFO Error Interrupt Clear Register Register
      [0] TXEICR ro — Clear Transmit FIFO Overflow/Underflow Interrupt.
    0x3C RXOICR — Receive FIFO Overflow Interrupt Clear Register
      [0] RXOICR ro — Clear Receive FIFO Overflow Interrupt.
    0x40 RXUICR — Receive FIFO Underflow Interrupt Clear Register
      [0] RXUICR ro — Clear Receive FIFO Underflow Interrupt.
    0x44 MSTICR — Multi-Controller Interrupt Clear Register
      [0] MSTICR ro — Clear Multi-Controller Contention Interrupt.
    0x48 ICR — Interrupt Clear Register
      [0] ICR ro — Clear Interrupts.
    0x4C DMACR — DMA Control Register
      fields as CONTROLLERCORE.CORE.DMACR
    0x50 DMATDLR — DMA Transmit Data Level
      fields as CONTROLLERCORE.CORE.DMATDLR
    0x54 DMARDLR — DMA Receive Data Level
      fields as CONTROLLERCORE.CORE.DMARDLR
    0x58 IDR reset 0x51535049 — Identification Register
      fields as CONTROLLERCORE.CORE.IDR
    0x5C SSICVERSIONID reset 0x3230312A — MSPI CORE component version
      fields as CONTROLLERCORE.CORE.SSICVERSIONID
    {0x60+4k} DR[{k}] (k=0..35) — Description collection: MSPI CORE Data Register 0
      fields as CONTROLLERCORE.CORE.DR[0]
    0xF0 RXSAMPLEDELAY
      fields as CONTROLLERCORE.CORE.RXSAMPLEDELAY
    0xF4 SPICTRLR0 reset 0x40000200 — SPI_CTRLR0 - SPI Control Register
      fields as CONTROLLERCORE.CORE.SPICTRLR0
    0xFC XIPMODEBITS — eXecute in Place - Mode bits
      [31:16] RSVDXIPMDBITS ro
      [15:0] XIPMDBITS — XIP mode bits to be sent after address phase of XIP transfer.
    0x100 XIPINCRINST — XIP_INCR_INST - XIP INCR transfer opcode
      [15:0] INCRINST — XIP INCR transfer opcode.
    0x104 XIPWRAPINST — XIP_WRAP_INST - XIP WRAP transfer opcode
      [15:0] WRAPINST — XIP WRAP transfer opcode.
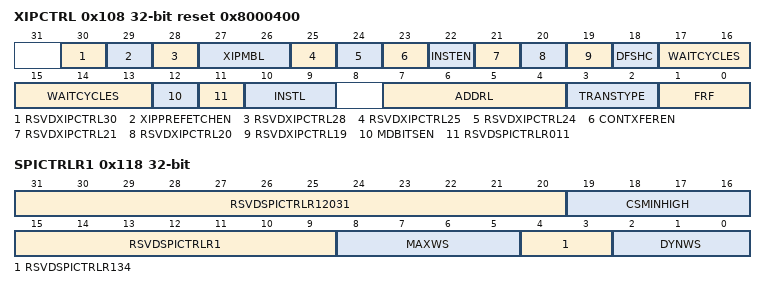
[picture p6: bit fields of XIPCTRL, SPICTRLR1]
    0x108 XIPCTRL reset 0x8000400 — XIP_CTRL - XIP Control Register
      [30] RSVDXIPCTRL30 ro
      [29] XIPPREFETCHEN — Enables XIP pre-fetch functionality in MSPI CORE.
      [28] RSVDXIPCTRL28 ro
      [27:26] XIPMBL — XIP Mode bits length. Sets the length of mode bits in XIP mode of operation. These bits are valid only when XIP_CTRL.XIP_MD_BIT_EN is set to 1.
        0=MBL_2 (Mode bits length equal to 2); 1=MBL_4 (Mode bits length equal to 4); 2=MBL_8 (Mode bits length equal to 8); 3=MBL_16 (Mode bits length equal to 16)
      [25] RSVDXIPCTRL25 ro
      [24] RSVDXIPCTRL24 ro
      [23] CONTXFEREN — Enable continuous transfer in XIP mode. If this bit is set to 1 then continuous transfer mode in XIP will be enabled, in this mode MSPI CORE will keep target selected until a non-XIP transfer is detected on the AHB interface.
      [22] INSTEN — XIP instruction enable bit. If this bit is set to 1 then XIP transfers will also have instruction phase. The instruction op-codes will be chosen from XIP_INCR_INST or XIP_WRAP_INST registers bases on AHB transfer type.
      [21] RSVDXIPCTRL21 ro
      [20] RSVDXIPCTRL20 ro
      [19] RSVDXIPCTRL19 ro
      [18] DFSHC — Fix DFS for XIP transfers. If this bit is set to 1 then data frame size for XIP transfers will be fixed to the programmed value in CTRLR0.DFS. The number of data frames to fetch will be determined by HSIZE and HBURST signals. If this bit is set to 0 then data frame size and number of data frames to fetch will be determined by HSIZE and HBURST signals
      [17:13] WAITCYCLES — Wait cycles in SPI mode between control frames transmit and data transmit/reception. Specified as number of SPI clock cycles.
      [12] MDBITSEN — Mode bits enable in XIP mode. If this bit is set to 1, then in XIP mode of operation MSPI CORE will insert mode bits after the address phase. These bits are set in register XIP_MODE_BITS register.
      [11] RSVDSPICTRLR011 ro
      [10:9] INSTL — Enhanced SPI mode instruction length in bits.
        values as CONTROLLERCORE.CORE.SPICTRLR0.INSTL
      [7:4] ADDRL — This bit defines Length of Address to be transmitted. Only after this much bits are programmed in to the FIFO the transfer can begin.
        values as CONTROLLERCORE.CORE.SPICTRLR0.ADDRL
      [3:2] TRANSTYPE — Address and instruction transfer format.
        0=TT0 (Instruction and Address will be sent in Standard SPI Mode.); 1=TT1 (Instruction will be sent in Standard SPI Mode and Address will be sent in the mode specified by XIP_CTRL.SPI_FRF.); 2=TT2 (Both Instruction and Address will be sent in the mode specified by XIP_CTRL.SPI_FRF.); 3=TT3 (Dual Octal mode, the address and instruction are transferred in octal mode and data is transferred on 16 data lines.)
      [1:0] FRF — SPI Frame Format
        values as CONTROLLERCORE.CORE.CTRLR0.SPIFRF
    0x10C XIPSER — XIP Target Enable Register
      [3:0] SER — Chip Select Enable Flag.
    0x110 XRXOICR — XIP Receive FIFO Overflow Interrupt Clear Register
      [0] XRXOICR ro — Clear XIP Receive FIFO Overflow Interrupt.
    0x114 XIPCNTTIMEOUT — XIP time out register for continuous transfers
      [7:0] XTOC — XIP time out value in terms of hclk. Once target is selected in continuous XIP mode this counter will be used to de-select the target if there is no request for the time specified in the counter.
    0x118 SPICTRLR1 — SPI Control 1 register
      [31:20] RSVDSPICTRLR12031 ro
      [19:16] CSMINHIGH — Chip-Select Minimum HIGH period.
      [15:9] RSVDSPICTRLR1 ro
      [8:5] RSVDSPICTRLR158 ro
      [4:3] RSVDSPICTRLR134 ro
      [2:0] RSVDSPICTRLR102 ro
